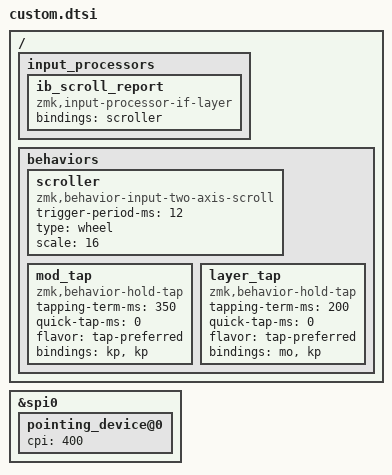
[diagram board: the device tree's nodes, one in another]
#include <dt-bindings/zmk/input_transform.h>

/ {
    /* 
     * input_processors ノード内に定義することで、
     * システム側の Binding (zmk,input-processor-if-layer) と紐付けます。
     */
    input_processors {
        ib_scroll_report: ib_scroll_report {
            compatible = "zmk,input-processor-if-layer";
            #input-processor-cells = <2>;
            bindings = <&scroller>;
        };
    };

    behaviors {
        // スクロール挙動
        scroller: scroller {
            compatible = "zmk,behavior-input-two-axis-scroll";
            #binding-cells = <0>;
            trigger-period-ms = <12>;
            type = "wheel";
            scale = <16>;
        };

        // Mod-Tap 上書き
        mod_tap: mod_tap {
            compatible = "zmk,behavior-hold-tap";
            #binding-cells = <2>;
            tapping-term-ms = <350>;
            quick-tap-ms = <0>;
            flavor = "tap-preferred";
            bindings = <&kp>, <&kp>;
        };

        // Layer-Tap 上書き
        layer_tap: layer_tap {
            compatible = "zmk,behavior-hold-tap";
            #binding-cells = <2>;
            tapping-term-ms = <200>;
            quick-tap-ms = <0>;
            flavor = "tap-preferred";
            bindings = <&mo>, <&kp>;
        };
    };
};

/*
 * 【アドレスエラー・未定義ラベル対策：最終版】
 * モジュールが定義した実際のSPIアドレス空間に直接アクセスし、
 * 既存のポインティングデバイス（PAW3222）のCPI設定だけを上書きします。
 */
&spi0 {
    pointing_device@0 {
        /* すでに存在するプロパティを安全に削除して上書き */
        /delete-property/ cpi;
        cpi = <400>;
    };
};
